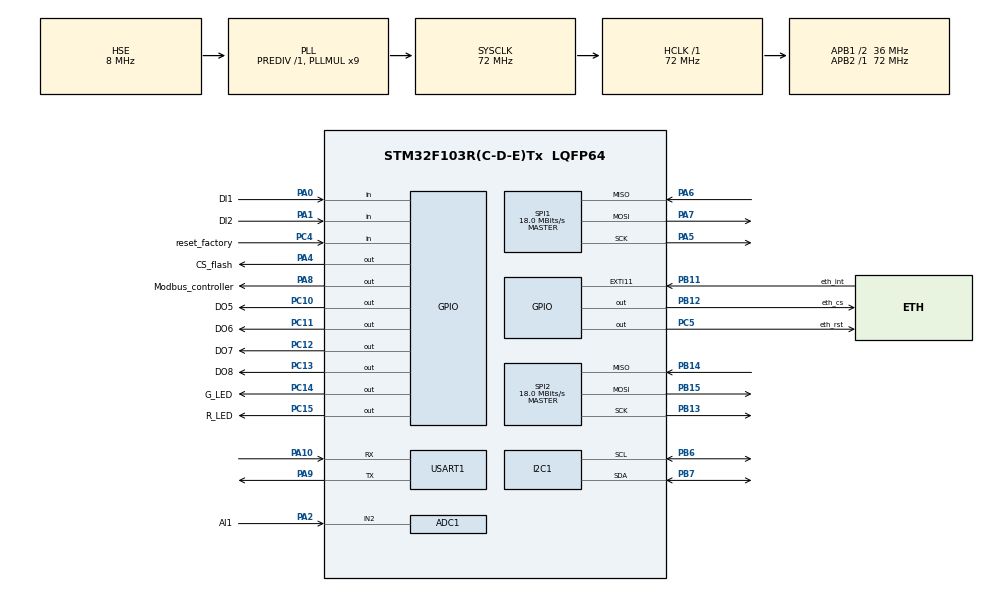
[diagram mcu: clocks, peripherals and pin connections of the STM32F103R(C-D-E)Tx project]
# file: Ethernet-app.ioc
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ADC1.Channel-0\#ChannelRegularConversion=ADC_CHANNEL_2
ADC1.NbrOfConversionFlag=1
ADC1.Rank-0\#ChannelRegularConversion=1
ADC1.SamplingTime-0\#ChannelRegularConversion=ADC_SAMPLETIME_1CYCLE_5
ADC1.master=1
Mcu.Family=STM32F1
Mcu.Name=STM32F103R(C-D-E)Tx
Mcu.Package=LQFP64
NVIC.PriorityGroup=NVIC_PRIORITYGROUP_4
NVIC.USART1_IRQn=true\:0\:0\:false\:false\:true\:true\:true\:true
PA0-WKUP.GPIO_Label=DI1
PA0-WKUP.GPIO_PuPd=GPIO_PULLDOWN
PA0-WKUP.Signal=GPIO_Input
PA1.GPIO_Label=DI2
PA1.GPIO_PuPd=GPIO_PULLDOWN
PA1.Signal=GPIO_Input
PA10.Mode=Asynchronous
PA10.Signal=USART1_RX
PA13.Signal=SYS_JTMS-SWDIO
PA14.Signal=SYS_JTCK-SWCLK
PA2.GPIO_Label=AI1
PA2.Signal=ADCx_IN2
PA4.GPIO_Label=CS_flash
PA4.GPIO_Speed=GPIO_SPEED_FREQ_HIGH
PA4.PinState=GPIO_PIN_SET
PA4.Signal=GPIO_Output
PA5.Mode=Full_Duplex_Master
PA5.Signal=SPI1_SCK
PA6.Mode=Full_Duplex_Master
PA6.Signal=SPI1_MISO
PA7.Mode=Full_Duplex_Master
PA7.Signal=SPI1_MOSI
PA8.GPIO_Label=Modbus_controller
PA8.GPIO_Speed=GPIO_SPEED_FREQ_HIGH
PA8.Signal=GPIO_Output
PA9.Mode=Asynchronous
PA9.Signal=USART1_TX
PB11.GPIO_Label=eth_int
PB11.GPIO_PuPd=GPIO_PULLUP
PB11.Signal=GPXTI11
PB12.GPIO_Label=eth_cs
PB12.GPIO_Speed=GPIO_SPEED_FREQ_HIGH
PB12.PinState=GPIO_PIN_SET
PB12.Signal=GPIO_Output
PB13.Mode=Full_Duplex_Master
PB13.Signal=SPI2_SCK
PB14.Mode=Full_Duplex_Master
PB14.Signal=SPI2_MISO
PB15.Mode=Full_Duplex_Master
PB15.Signal=SPI2_MOSI
PB6.Mode=I2C
PB6.Signal=I2C1_SCL
PB7.Mode=I2C
PB7.Signal=I2C1_SDA
PC10.GPIO_Label=DO5
PC10.GPIO_Speed=GPIO_SPEED_FREQ_HIGH
PC10.PinState=GPIO_PIN_RESET
PC10.Signal=GPIO_Output
PC11.GPIO_Label=DO6
PC11.GPIO_Speed=GPIO_SPEED_FREQ_HIGH
PC11.Signal=GPIO_Output
PC12.GPIO_Label=DO7
PC12.GPIO_Speed=GPIO_SPEED_FREQ_HIGH
PC12.Signal=GPIO_Output
PC13-TAMPER-RTC.GPIO_Label=DO8
PC13-TAMPER-RTC.GPIO_Speed=GPIO_SPEED_FREQ_HIGH
PC13-TAMPER-RTC.Signal=GPIO_Output
PC14-OSC32_IN.GPIO_Label=G_LED
PC14-OSC32_IN.Signal=GPIO_Output
PC15-OSC32_OUT.GPIO_Label=R_LED
PC15-OSC32_OUT.Signal=GPIO_Output
PC4.GPIO_Label=reset_factory
PC4.GPIO_PuPd=GPIO_PULLUP
PC4.Signal=GPIO_Input
PC5.GPIO_Label=eth_rst
PC5.GPIO_Speed=GPIO_SPEED_FREQ_HIGH
PC5.PinState=GPIO_PIN_SET
PC5.Signal=GPIO_Output
PC6.GPIO_Label=DOPWM1
PC6.Signal=S_TIM3_CH1
PC7.GPIO_Label=DOPWM2
PC7.Signal=S_TIM3_CH2
PC8.GPIO_Label=DOPWM3
PC8.Signal=S_TIM3_CH3
PC9.GPIO_Label=DOPWM4
PC9.Signal=S_TIM3_CH4
PD0-OSC_IN.Mode=HSE-External-Oscillator
PD0-OSC_IN.Signal=RCC_OSC_IN
PD1-OSC_OUT.Mode=HSE-External-Oscillator
PD1-OSC_OUT.Signal=RCC_OSC_OUT
ProjectManager.HeapSize=0x200
ProjectManager.StackSize=0x400
ProjectManager.TargetToolchain=STM32CubeIDE
RCC.ADCPresc=RCC_ADCPCLK2_DIV6
RCC.AHBFreq_Value=72000000
RCC.APB1CLKDivider=RCC_HCLK_DIV2
RCC.APB1Freq_Value=36000000
RCC.APB1TimFreq_Value=72000000
RCC.APB2Freq_Value=72000000
RCC.APB2TimFreq_Value=72000000
RCC.HCLKFreq_Value=72000000
RCC.PLLMUL=RCC_PLL_MUL9
RCC.PLLSourceVirtual=RCC_PLLSOURCE_HSE
RCC.SYSCLKFreq_VALUE=72000000
RCC.SYSCLKSource=RCC_SYSCLKSOURCE_PLLCLK
RCC.USBFreq_Value=72000000
SH.ADCx_IN2.0=ADC1_IN2,IN2
SH.S_TIM3_CH1.0=TIM3_CH1
SH.S_TIM3_CH2.0=TIM3_CH2
SH.S_TIM3_CH3.0=TIM3_CH3
SH.S_TIM3_CH4.0=TIM3_CH4
SPI1.BaudRatePrescaler=SPI_BAUDRATEPRESCALER_4
SPI1.CalculateBaudRate=18.0 MBits/s
SPI1.DataSize=SPI_DATASIZE_8BIT
SPI1.Direction=SPI_DIRECTION_2LINES
SPI1.Mode=SPI_MODE_MASTER
SPI1.VirtualType=VM_MASTER
SPI2.CalculateBaudRate=18.0 MBits/s
SPI2.DataSize=SPI_DATASIZE_8BIT
SPI2.Direction=SPI_DIRECTION_2LINES
SPI2.Mode=SPI_MODE_MASTER
SPI2.VirtualType=VM_MASTER
USART1.VirtualMode=VM_ASYNC
VP_CRC_VS_CRC.Mode=CRC_Activate
VP_SYS_VS_ND.Mode=No_Debug
board=custom

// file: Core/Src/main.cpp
/* USER CODE BEGIN Header */
/**
 ******************************************************************************
 * @file           : main.c
 * @brief          : Main program body
 ******************************************************************************
 * @attention
 *
 * Copyright (c) 2023 STMicroelectronics.
 * All rights reserved.
 *
 * This software is licensed under terms that can be found in the LICENSE file
 * in the root directory of this software component.
 * If no LICENSE file comes with this software, it is provided AS-IS.
 *
 ******************************************************************************
 */
/* USER CODE END Header */
#include "main.h"
#include "adc.h"
#include "crc.h"
#include "i2c.h"
#include "spi.h"
#include "usart.h"
#include "gpio.h"

/* USER CODE BEGIN Includes */
#include "app.h"
/* USER CODE END Includes */

void SystemClock_Config(void);

/* USER CODE BEGIN 0 */
void logua(const char *string) {
	size_t len = strlen(string);
	HAL_GPIO_WritePin(Modbus_controller_GPIO_Port, Modbus_controller_Pin,
			GPIO_PIN_SET);
	HAL_UART_Transmit(&huart1, (uint8_t*) string, len, HAL_MAX_DELAY); // transmit in blocking mode
}
/* USER CODE END 0 */

app *app1 = nullptr;
int main(void) {

	/* MCU Configuration--------------------------------------------------------*/

	/* Reset of all peripherals, Initializes the Flash interface and the Systick. */
	HAL_Init();

	/* Configure the system clock */
	SystemClock_Config();

	/* Initialize all configured peripherals */
	// Configure and enable the watchdog timer

//	MX_IWDG_Init();
//	hiwdg.Instance = IWDG;
//	    hiwdg.Init.Prescaler = IWDG_PRESCALER_256;
//	    hiwdg.Init.Reload = 0xFF;  // Timeout value, adjust as needed
//	    if (HAL_IWDG_Init(&hiwdg) != HAL_OK) {
//	        Error_Handler();
//	    }
	MX_GPIO_Init();
	MX_CRC_Init();
	MX_SPI1_Init();
	MX_SPI2_Init();
	MX_ADC1_Init();
	MX_I2C1_Init();
	MX_USART1_UART_Init();
	// Set up UART
	//HAL_UART_Init(&huart1);

	// Enable UART transmit interrupt

	/* Infinite loop */
	/* USER CODE BEGIN WHILE */
	app1 = new app(hspi1, hspi2, huart1);
	HAL_GPIO_WritePin(Modbus_controller_GPIO_Port, Modbus_controller_Pin,
						GPIO_PIN_RESET);
	while (1) {
		/* USER CODE END WHILE */
		//HAL_IWDG_Refresh(&hiwdg);
		app1->loop();
	}
}

// UART transmit interrupt handler
void HAL_UART_TxCpltCallback(UART_HandleTypeDef *huart) {
	// This function is called when the UART transmission is complete
	// You can load the next byte of data here
	HAL_GPIO_WritePin(Modbus_controller_GPIO_Port, Modbus_controller_Pin,
			GPIO_PIN_RESET);
}
// UART receive interrupt handler
void HAL_UART_RxCallback() {
	// This function is called when new data is received
	// You can read the received data from huart->Instance->DR
	app1->serial_int();

}
void SystemClock_Config(void) {
	RCC_OscInitTypeDef RCC_OscInitStruct = { 0 };
	RCC_ClkInitTypeDef RCC_ClkInitStruct = { 0 };

	/** Initializes the RCC Oscillators according to the specified parameters
	 * in the RCC_OscInitTypeDef structure.
	 */
	RCC_OscInitStruct.OscillatorType = RCC_OSCILLATORTYPE_HSE;
	RCC_OscInitStruct.HSEState = RCC_HSE_ON;
	RCC_OscInitStruct.HSEPredivValue = RCC_HSE_PREDIV_DIV1;
	RCC_OscInitStruct.HSIState = RCC_HSI_ON;
	RCC_OscInitStruct.PLL.PLLState = RCC_PLL_ON;
	RCC_OscInitStruct.PLL.PLLSource = RCC_PLLSOURCE_HSE;
	RCC_OscInitStruct.PLL.PLLMUL = RCC_PLL_MUL9;
	if (HAL_RCC_OscConfig(&RCC_OscInitStruct) != HAL_OK) {
		Error_Handler();
	}

	/** Initializes the CPU, AHB and APB buses clocks
	 */
	RCC_ClkInitStruct.ClockType = RCC_CLOCKTYPE_HCLK | RCC_CLOCKTYPE_SYSCLK
			| RCC_CLOCKTYPE_PCLK1 | RCC_CLOCKTYPE_PCLK2;
	RCC_ClkInitStruct.SYSCLKSource = RCC_SYSCLKSOURCE_PLLCLK;
	RCC_ClkInitStruct.AHBCLKDivider = RCC_SYSCLK_DIV1;
	RCC_ClkInitStruct.APB1CLKDivider = RCC_HCLK_DIV2;
	RCC_ClkInitStruct.APB2CLKDivider = RCC_HCLK_DIV1;

	if (HAL_RCC_ClockConfig(&RCC_ClkInitStruct, FLASH_LATENCY_2) != HAL_OK) {
		Error_Handler();
	}
}

void Error_Handler(void) {
	__disable_irq();
	while (1) {
	}
}
